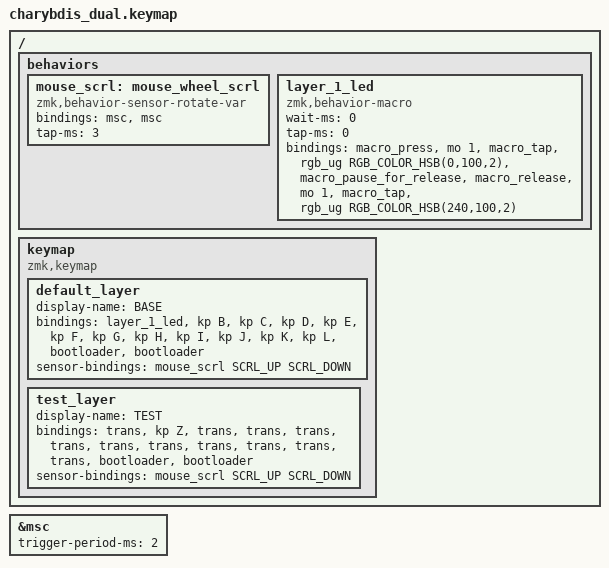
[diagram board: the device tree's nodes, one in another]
#define ZMK_POINTING_DEFAULT_SCRL_VAL 500

#include <behaviors.dtsi>
#include <dt-bindings/zmk/keys.h>
#include <dt-bindings/zmk/pointing.h>
#include <dt-bindings/zmk/rgb.h>


&msc {
    trigger-period-ms = <2>;
};


/ {
    behaviors {
        /*
         * スクロールホイール
         */
        mouse_scrl: mouse_wheel_scrl {
            compatible = "zmk,behavior-sensor-rotate-var";
            #sensor-binding-cells = <2>;

            bindings = <&msc>, <&msc>;

            tap-ms = <3>;
        };


        /*
         * Layer 1キー
         *
         * 押した瞬間:
         *   Layer 1 ON
         *   LED = RED
         *
         * 離した瞬間:
         *   Layer 1 OFF
         *   LED = BLUE
         */
        layer_1_led: layer_1_led {
            compatible = "zmk,behavior-macro";
            #binding-cells = <0>;

            wait-ms = <0>;
            tap-ms = <0>;

            bindings
                = <&macro_press &mo 1>
                , <&macro_tap &rgb_ug RGB_COLOR_HSB(0,100,2)>
                , <&macro_pause_for_release>
                , <&macro_release &mo 1>
                , <&macro_tap &rgb_ug RGB_COLOR_HSB(240,100,2)>
                ;
        };
    };


    keymap {
        compatible = "zmk,keymap";


        /*
         * Layer 0
         */
        default_layer {
            display-name = "BASE";

            bindings = <
                /* LEFT */
                &layer_1_led
                &kp B
                &kp C
                &kp D
                &kp E
                &kp F

                /* RIGHT */
                &kp G
                &kp H
                &kp I
                &kp J
                &kp K
                &kp L

                /*
                 * 専用BOOT
                 *
                 * position 12:
                 * 左D6 / ドングルD6
                 *
                 * position 13:
                 * 右D6
                 */
                &bootloader
                &bootloader
            >;

            sensor-bindings = <
                &mouse_scrl SCRL_UP SCRL_DOWN
            >;
        };


        /*
         * Layer 1
         */
        test_layer {
            display-name = "TEST";

            bindings = <
                /* LEFT */
                &trans
                &kp Z
                &trans
                &trans
                &trans
                &trans

                /* RIGHT */
                &trans
                &trans
                &trans
                &trans
                &trans
                &trans

                /*
                 * どのLayerにいても
                 * 専用BOOTボタンは有効
                 */
                &bootloader
                &bootloader
            >;

            sensor-bindings = <
                &mouse_scrl SCRL_UP SCRL_DOWN
            >;
        };
    };
};
